# VPAC0_COMMON_0_IVPAC_TOP_0_CFG_SLV_PAR_VPAC_MSC_CFG_VP_CFG_VP register map
Vendor: Texas Instruments
Peripheral module from a debugger description file (folder am62A).
Registers are 32-bit, read-write, reset 0x0 unless marked. A register's access mark holds for its fields unless they carry their own. Offsets are as the file gives them; lines under a group give offsets from that group; [hi:lo] are bit positions; {n}, {i} and the like mark numbered series; 'fields as' and 'values as' point back to an identical list; <NAME> marks a mode.

## VPAC0_COMMON_0_IVPAC_TOP_0_CFG_SLV_PAR_VPAC_MSC_CFG_VP_CFG_VP
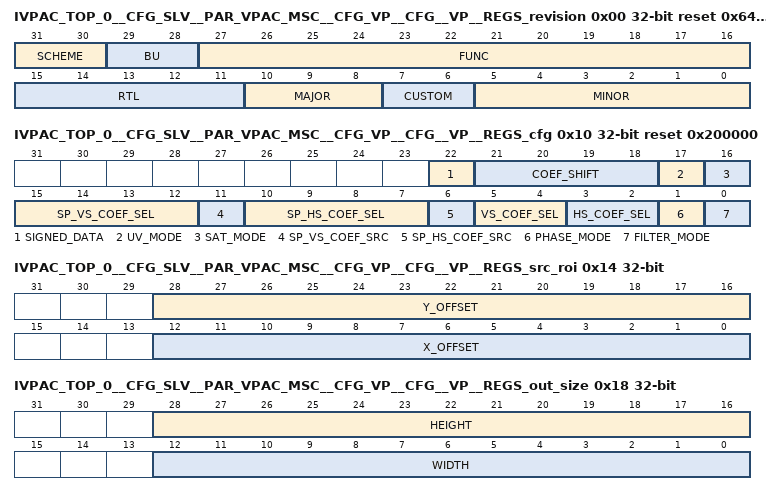
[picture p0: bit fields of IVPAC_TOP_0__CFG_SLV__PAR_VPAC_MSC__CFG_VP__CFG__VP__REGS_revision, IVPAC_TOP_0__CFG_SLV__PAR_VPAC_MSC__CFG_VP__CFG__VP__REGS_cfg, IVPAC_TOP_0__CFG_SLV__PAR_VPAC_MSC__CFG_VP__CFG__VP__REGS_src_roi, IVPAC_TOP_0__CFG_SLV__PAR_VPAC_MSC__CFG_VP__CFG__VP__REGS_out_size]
0x00 IVPAC_TOP_0__CFG_SLV__PAR_VPAC_MSC__CFG_VP__CFG__VP__REGS_revision ro reset 0x64C20100 — The REVISION Register contains the major and minor revisions for the VPAC MSC HWA module.
  [31:30] SCHEME — Used to distinguish between old scheme and new scheme. Spare bit to encode future schemes
  [29:28] BU — BU indicator DSPS ==> 0x0 WTBU ==> 0x1 Processors ==> 0x2
  [27:16] FUNC — Function indicates a software compatible module family. If there is no level of software compatibility a new FUNC number, and hence PID, should be assigned.
  [15:11] RTL — RTL Version. R as described in PDR with additional clarifications and definitions below. Must be easily ECO-able or controlled during fabrication. Ideally through a top level metal mask or e-fuse. This number is maintained/owned by IP design owner. RTL follows a numbering such as X.Y.R.Z which are explained in this table. R changes ONLY when : (1) PDS uploads occur which may have been due to spec changes (2) Bug fixes occur (3) Resets to '0' when X or Y changes. Design team has an internal 'Z' (customer invisible) number which increments on every drop that happens due to DV and RTL updates. Z resets to 0 when R increments.
  [10:8] MAJOR — Major Revision. X as described in PDR with additional clarifications/definitions below. This number is owned/maintained by IP specification owner. X is part of IP numbering X.Y.R.Z. X changes ONLY when: (1) There is a major feature addition. An example would be adding Master Mode to Utopia Level2. The Func field (or Class/Type in old PID format) will remain the same. X does NOT change due to: (1) Bug fixes (2) Change in feature parameters.
  [7:6] CUSTOM — Indicates a special version for a particular device. Consequence of use may avoid use of standard Chip Support Library (CSL) / Drivers. 0 if non-c ustom.
  [5:0] MINOR — Minor Revision. Y as described in PDR with additional clarifications/definitions below. This number is owned/maintained by IP specification owne r. Y changes ONLY when: (1) Features are scaled (up or down). Flexibility exists in that this feature scalability may either be represented in the Y change or a specific register in the IP that indica tes which features are exactly available. (2) When feature creeps from Is-Not list to Is list. But this may not be the case once it sees silicon - in which case X will change. Y does NOT change due to : (1) Bug fixes (2) Typos or clarifications (3) major functional/feature change/addition/deletion. Instead these changes may be reflected via R, S, X as applicable. Spec owner maintains a customer-invisible number 'S' which changes due to: (1) Typos/clarifications (2) Bug documentation. Note that this bug is not due to a spec change but due to implementation. Nevertheless, the spec tracks the I P bugs. An RTL release (say for silicon PG1.1) that occurs due to bug fix should document the corresponding spec number (X.Y.S) in its release notes.
0x04 IVPAC_TOP_0__CFG_SLV__PAR_VPAC_MSC__CFG_VP__CFG__VP__REGS_control — The CONTROL Register allows the CPU to control various aspects of the module.
  [0] MSC_ENABLE — MSC Core Enable: Enables the MSC HWA. (Must be enabled even when MSC is strictly in the loopback-only mode. Individual resizing filter is enabled only when the output buffer associated with the filter is enabled in the LSE configuration.) 0: Disable 1: Enable
0x10 IVPAC_TOP_0__CFG_SLV__PAR_VPAC_MSC__CFG_VP__CFG__VP__REGS_cfg reset 0x200000 — The FILT[a]_CFG register configures the modes of FILTER channel [a].
  [22] SIGNED_DATA — Integer type of input and output frame data: 0 : Unsigned 12-bit (default) 1 : Signed 12-bit
  [21:18] COEF_SHIFT — Coef Shift Size: configures the precision of the 10-bit signed filter coefficients (valid Shift range: 5~9) : 5: Shift by 5 (5-bit fraction) 6: Shift by 6 (6-bit fraction) 7: Shift by 7 (7-bit fraction) 8: Shift by 8 (8-bit fraction) 9: Shift by 9 (9-bit fraction) Integer size = 9 - #_of_fraction_bits
  [17] UV_MODE — Source data interleave format: 0 - non-interleaved (Y data) 1 - interleaved (UV data)
  [16] SAT_MODE — Filter Output Saturation Mode 0 - [0..4095] clipping 1 - [-2048.. 2047] clip followed by +2048 This is used only when signed_data=0 (unsigned data type).
  [15:12] SP_VS_COEF_SEL — Single Phase Vertical Filter Coef Selection (sp_vs_coef_src = 0) 0000 : Use Dedicated SP coef-0 0001 : Use Dedicated SP coef-1 (sp_hs_coef_src = 1) N : Use (N+16)th entry of 5-tap/32-phase filter coef set 0 (N = 0..15)
  [11] SP_VS_COEF_SRC — Single Phase Vertical Filter Coef Source Selection 0 : Use one of two dedicated single phase coeffs 1 : Use the custom single phase coeff table (5-tap/32-phase Filter coef set 0) If set to 1, 5-tap/32-phase filter coef set-0 is to be dedicated for specifying addtional single phase filter coefficients.
  [10:7] SP_HS_COEF_SEL — Single Phase Horizontal Filter Coef Selection (sp_hs_coef_src = 0) 0000 : Use Dedicated SP coef-0 0001 : Use Dedicated SP coef-1 (sp_hs_coef_src = 1) N : Use Nth entry of 5-tap/32-phase filter coef set 0 (N = 0..15)
  [6] SP_HS_COEF_SRC — Single Phase Horizontal Filter Coef Source Selection 0 : Use one of two dedicated single phase coeffs 1 : Use the custom single phase coeff table (5-tap/32-phase Filter coef set 0) If set to 1, 5-tap/32-phase filter coef set-0 is to be dedicated for specifying additional single phase filter coefficients.
  [5:4] VS_COEF_SEL — Multi-phase Vertical Coef Selection (Phase_mode=0) 00 : 5-tap/32-phase Filter coef sets 0 & 1 10 : 5-tap/32-phase Filter Coef sets 2 & 3 (Phase_mode=1) 00 : 5-tap/32-phase Filter coef set 0 01 : 5-tap/32-phase Filter coef set 1 10 : 5-tap/32-phase Filter coef set 2 11 : 5-tap/32-phase Filter coef set 3
  [3:2] HS_COEF_SEL — Multi-phase Horizontal Coef Selection (Phase_mode=0) 00 : 5-tap/32-phase Filter coef sets 0 & 1 10 : 5-tap/32-phase Filter Coef sets 2 & 3 (Phase_mode=1) 00 : 5-tap/32-phase Filter coef set 0 01 : 5-tap/32-phase Filter coef set 1 10 : 5-tap/32-phase Filter coef set 2 11 : 5-tap/32-phase Filter coef set 3
  [1] PHASE_MODE — Filter Phase mode selection 0 - 64 phases 1 - 32 phases
  [0] FILTER_MODE — Filter Mode 0 : Single Phase Filter (e.g., Gaussian Filter for Pyramid generation) 1: Multi-phase Scaling Filter
0x14 IVPAC_TOP_0__CFG_SLV__PAR_VPAC_MSC__CFG_VP__CFG__VP__REGS_src_roi — The FILT[a]_SRC_ROI register configures the input ROI position within the input super frame for FILTER channel [a]. Set to 0 if ROI is full-size.
  [28:16] Y_OFFSET — Source Y offset
  [12:0] X_OFFSET — Source X offset (Must be an even # when FILT_CFG.uv_mode=1)
0x18 IVPAC_TOP_0__CFG_SLV__PAR_VPAC_MSC__CFG_VP__CFG__VP__REGS_out_size — The FILT[a]_OUT_SIZE configures the output size for FILTER channel [a].
  [28:16] HEIGHT — Output Height
  [12:0] WIDTH — Output Width
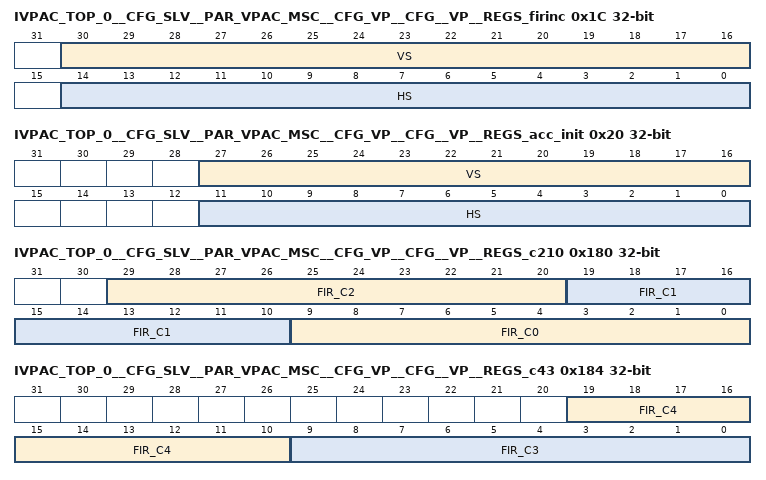
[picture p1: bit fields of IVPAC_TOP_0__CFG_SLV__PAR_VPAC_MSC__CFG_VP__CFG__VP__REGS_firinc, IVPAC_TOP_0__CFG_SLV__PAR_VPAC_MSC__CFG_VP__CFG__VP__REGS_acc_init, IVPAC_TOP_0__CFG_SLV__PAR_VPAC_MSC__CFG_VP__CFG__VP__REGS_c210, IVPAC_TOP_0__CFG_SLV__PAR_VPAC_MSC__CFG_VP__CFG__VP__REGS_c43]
0x1C IVPAC_TOP_0__CFG_SLV__PAR_VPAC_MSC__CFG_VP__CFG__VP__REGS_firinc — The FILT[a]_FIRINC register configures the FIRINC attributes of FILTER channel [a].
  [30:16] VS — FIRINC of VS filter
  [14:0] HS — FIRINC of HS filter
0x20 IVPAC_TOP_0__CFG_SLV__PAR_VPAC_MSC__CFG_VP__CFG__VP__REGS_acc_init — The FILT[a]_ACC_INIT register configures the FIRINC attributes of FILTER channel [a].
  [27:16] VS — ACC_INIT of VS filter
  [11:0] HS — ACC_INIT of HS filter
0x180 IVPAC_TOP_0__CFG_SLV__PAR_VPAC_MSC__CFG_VP__CFG__VP__REGS_c210 — Single Phase Coef Set[a] coefficients C2/C1/C0
  [29:20] FIR_C2 — Signed coefficient C2
  [19:10] FIR_C1 — Signed coefficient C1
  [9:0] FIR_C0 — Signed coefficient C0
0x184 IVPAC_TOP_0__CFG_SLV__PAR_VPAC_MSC__CFG_VP__CFG__VP__REGS_c43 — Single Phase Coef Set[a] coefficients C4/C3
  [19:10] FIR_C4 — Signed coefficient C4
  [9:0] FIR_C3 — Signed coefficient C3
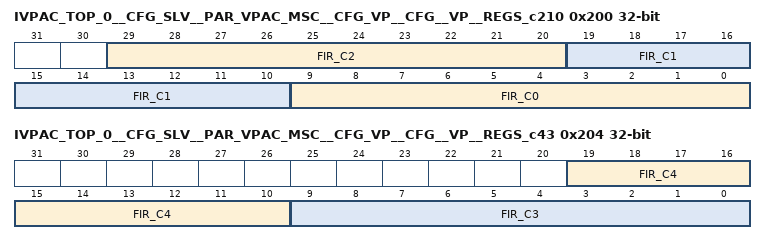
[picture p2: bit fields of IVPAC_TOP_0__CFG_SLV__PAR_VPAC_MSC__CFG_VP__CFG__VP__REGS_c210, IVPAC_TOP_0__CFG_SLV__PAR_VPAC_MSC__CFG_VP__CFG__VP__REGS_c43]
0x200 IVPAC_TOP_0__CFG_SLV__PAR_VPAC_MSC__CFG_VP__CFG__VP__REGS_c210 — Multi Phase Coef Set[a] Phase[b] coefficients C2/C1/C0
  fields as IVPAC_TOP_0__CFG_SLV__PAR_VPAC_MSC__CFG_VP__CFG__VP__REGS_c210
0x204 IVPAC_TOP_0__CFG_SLV__PAR_VPAC_MSC__CFG_VP__CFG__VP__REGS_c43 — Multi Phase Coef Set[a] Phase[b] coefficients C4/C3
  fields as IVPAC_TOP_0__CFG_SLV__PAR_VPAC_MSC__CFG_VP__CFG__VP__REGS_c43
